# timer_a register map
Vendor: Texas Instruments
Peripheral module from a debugger description file (folder MSP432).
Registers are 16-bit, read-write, no defined reset value unless marked. A register's access mark holds for its fields unless they carry their own. Offsets are as the file gives them; lines under a group give offsets from that group; [hi:lo] are bit positions; {n}, {i} and the like mark numbered series; 'fields as' and 'values as' point back to an identical list; <NAME> marks a mode.

## Timer_A
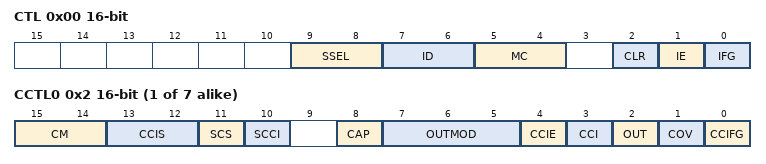
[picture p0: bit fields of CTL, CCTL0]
0x00 CTL — TimerAx Control Register
  [9:8] SSEL — TimerA clock source select
    0=SSEL__0 (TAxCLK); 1=SSEL__1 (ACLK); 2=SSEL__2 (SMCLK); 3=SSEL__3 (INCLK)
  [7:6] ID — Input divider
    0=ID__0 (/1); 1=ID__1 (/2); 2=ID__2 (/4); 3=ID__3 (/8)
  [5:4] MC — Mode control
    0=MC__0 (Stop mode: Timer is halted); 1=MC__1 (Up mode: Timer counts up to TAxCCR0); 2=MC__2 (Continuous mode: Timer counts up to 0FFFFh); 3=MC__3 (Up/down mode: Timer counts up to TAxCCR0 then down to 0000h)
  [2] CLR — TimerA clear
  [1] IE — TimerA interrupt enable
    0=IE__0 (Interrupt disabled); 1=IE__1 (Interrupt enabled)
  [0] IFG — TimerA interrupt flag
    0=IFG__0 (No interrupt pending); 1=IFG__1 (Interrupt pending)
{0x2+2i} CCTL{i} (i=0..6) — Timer_A Capture/Compare Control Register
  [15:14] CM — Capture mode
    0=CM__0 (No capture); 1=CM__1 (Capture on rising edge); 2=CM__2 (Capture on falling edge); 3=CM__3 (Capture on both rising and falling edges)
  [13:12] CCIS — Capture/compare input select
    0=CCIS__0 (CCIxA); 1=CCIS__1 (CCIxB); 2=CCIS__2 (GND); 3=CCIS__3 (VCC)
  [11] SCS — Synchronize capture source
    0=SCS__0 (Asynchronous capture); 1=SCS__1 (Synchronous capture)
  [10] SCCI — Synchronized capture/compare input
  [8] CAP — Capture mode
    0=CAP__0 (Compare mode); 1=CAP__1 (Capture mode)
  [7:5] OUTMOD — Output mode
    0=OUTMOD__0 (OUT bit value); 1=OUTMOD__1 (Set); 2=OUTMOD__2 (Toggle/reset); 3=OUTMOD__3 (Set/reset); 4=OUTMOD__4 (Toggle); 5=OUTMOD__5 (Reset); 6=OUTMOD__6 (Toggle/set); 7=OUTMOD__7 (Reset/set)
  [4] CCIE — Capture/compare interrupt enable
    0=CCIE__0 (Interrupt disabled); 1=CCIE__1 (Interrupt enabled)
  [3] CCI — Capture/compare input
  [2] OUT — Output
    0=OUT__0 (Output low); 1=OUT__1 (Output high)
  [1] COV — Capture overflow
    0=COV__0 (No capture overflow occurred); 1=COV__1 (Capture overflow occurred)
  [0] CCIFG — Capture/compare interrupt flag
    0=CCIFG__0 (No interrupt pending); 1=CCIFG__1 (Interrupt pending)
0x10 R access not given — TimerA register
{0x12+2i} CCR{i} (i=0..6) — Timer_A Capture/Compare Register
  [15:0] R — TimerA register. The TAxR register is the count of TimerA.
0x20 EX0 — TimerAx Expansion 0 Register
  [2:0] IDEX — Input divider expansion
    {v}=IDEX__{v} (Divide by {v+1}) (v=0..7)
0x2E IV — TimerAx Interrupt Vector Register
  [15:0] IV — TimerA interrupt vector value
    0=IV__0 (No interrupt pending); 2=IV__2 (Interrupt Source: Capture/compare 1; Interrupt Flag: TAxCCR1 CC); 4=IV__4 (Interrupt Source: Capture/compare 2; Interrupt Flag: TAxCCR2 CC); 6=IV__6 (Interrupt Source: Capture/compare 3; Interrupt Flag: TAxCCR3 CC); 8=IV__8 (Interrupt Source: Capture/compare 4; Interrupt Flag: TAxCCR4 CC); 10=IV__16 (Interrupt Source: Capture/compare 5; Interrupt Flag: TAxCCR5 CC); 12=IV__18 (Interrupt Source: Capture/compare 6; Interrupt Flag: TAxCCR6 CC); 14=IV__20 (Interrupt Source: Timer overflow; Interrupt Flag: TAxCTL TAIFG;)
